# PIC32CX2051BZ66048 device description
Architecture: CORTEX-M4; Family: PIC32CX; Series: PIC32CXBZ66
Registers are 32-bit, read-write, reset 0x0 unless marked. A register's access mark holds for its fields unless they carry their own. Offsets are from the block's base; [hi:lo] are bit positions; lines under a group give offsets from that group; {n}, {i} and the like mark numbered series.

## USB
Instances: USB 0x44010000
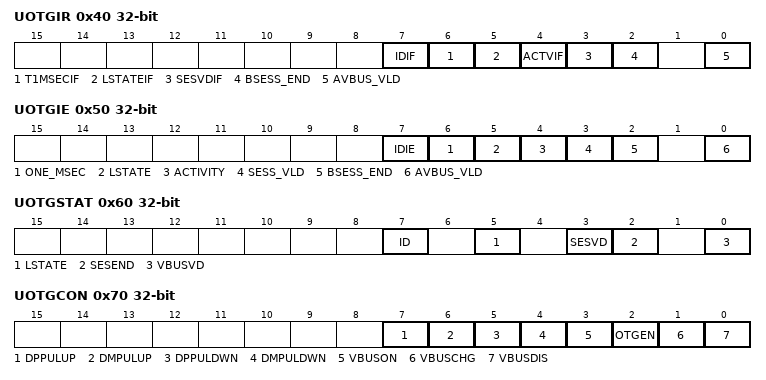
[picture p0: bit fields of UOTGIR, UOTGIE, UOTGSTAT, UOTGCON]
0x40 UOTGIR reset not defined — USB OTG Interrupt Status Register
  [7] IDIF — ID State Change Indicator bit
    1=DETECT (Change in ID state is detected); 0=NO_DETECT (No change in ID state is detected)
  [6] T1MSECIF — 1 Millisecond Timer bit
    1=EXPIRE (1ms timer has expired); 0=NOT_EXPIRE (1ms timer has not expired)
  [5] LSTATEIF — Line State Stable Indicator bit
    1=STABLE (USB line state has been stable for 1ms); 0=NOT_STABLE (USB line state has not been stable for 1ms)
  [4] ACTVIF — Bus Activity Indicator bit
    1=DETECT (Activity on the D+, D-, ID, or VBus lines has been detected); 0=NO_DETECT (Active has not been detected)
  [3] SESVDIF — Session Valid Change Indicator bit
    1=CHANGE (Change on usb_sess_vld input detected); 0=NO_CHANGED (No change on usb_sess_vld input detected)
  [2] BSESS_END — B-Device VBUS change indicator bit
    1=CHANGE (Change on usb_b_sess_end input detected); 0=NO_CHANGED (No change on usb_b_sess_end input detected)
  [0] AVBUS_VLD — A-VBUS change indicator bit
    1=CHANGE (Change on usb_a_vbus_vld input detected); 0=NO_CHANGE (No change on usb_a_vbus_vld input detected)
0x44 UOTGIRCLR
0x48 UOTGIRSET
0x4C UOTGIRINV
0x50 UOTGIE reset not defined — USB OTG Interrupt Enable Register
  [7] IDIE — ID Interrupt Enable bit
    1=ON (ID interrupt is enabled); 0=OFF (ID interrupt is disabled)
  [6] ONE_MSEC — 1 Millisecond Timer Interrupt Enable bit
    1=ON (1 millisecond timer interrupt is enabled); 0=OFF (1 millisecond timer interrupt is disabled)
  [5] LSTATE — Line State Interrupt Enable bit
    1=ON (Line state interrupt is enabled); 0=OFF (Line state interrupt is disabled)
  [4] ACTIVITY — Activity Interrupt Enable bit
    1=ON (ACTIVITY interrupt is enabled); 0=OFF (ACTIVITY interrupt is disabled)
  [3] SESS_VLD — Session Valid Interrupt Enable bit
    1=ON (Session valid interrupt is enabled); 0=OFF (Session valid interrupt is disabled)
  [2] BSESS_END — B-Session End Interrupt Enable bit
    1=ON (B-session end interrupt is enabled); 0=OFF (B-session end interrupt is disabled)
  [0] AVBUS_VLD — A- Vbus Valid Interrupt Enable bit
    1=ON (A-Vbus valid interrupt is enabled); 0=OFF (A-Vbus valid interrupt is disabled)
0x54 UOTGIECLR
0x58 UOTGIESET
0x5C UOTGIEINV
0x60 UOTGSTAT reset not defined — USB OTG Status Register
  [7] ID — ID Pin State Indicator bit
    1=NOT_PLUG (No cable is attached or a Type-B cable has been plugged into the USB receptacle); 0=PLUG (A Type-A cable has been plugged into the USB receptacle)
  [5] LSTATE — Line State Stable Indicator bit
    1=STABLE (USB line state (UCTRL[SE0 and JSTATE]) has been stable for the previous 1 ms); 0=NOT_STABLE (USB line state (UCTRL[SE0 and JSTATE]) has not been stable for the previous 1 ms)
  [3] SESVD — Session Valid Indicator bit
    1=ABOVE (Vbus voltage is above Session Valid on the A or B device); 0=BELOW (Vbus voltage is below Session Valid on the A or B device)
  [2] SESEND — B-Session End Indicator bit
    1=BELOW (Vbus voltage is below VB_SESS_END on the B device); 0=ABOVE (Vbus voltage is above VB_SESS_END on the B device)
  [0] VBUSVD — A-VBUS Valid Indicator bit
    1=ABOVE (Vbus voltage is above VA_VBUS_VLD on the A device); 0=BELOW (Vbus voltage is below VA_VBUS_VLD on the A device)
0x70 UOTGCON reset not defined — USB OTG Control Register
  [7] DPPULUP — D+ Pull-Up Enable bit
    1=ON (D+ data line pull-up resistor is enabled); 0=OFF (D+ data line pull-up resistor is disabled)
  [6] DMPULUP — D- Pull-Up Enable bit
    1=ON (D- data line pull-up resistor is enabled); 0=OFF (D- data line pull-up resistor is disabled)
  [5] DPPULDWN — D+ Pull-Down Enable bit
    1=ON (D+ data line pull-down resistor is enabled); 0=OFF (D+ data line pull-down resistor is disabled)
  [4] DMPULDWN — D- Pull-Down Enable bit
    1=ON (D- data line pull-down resistor is enabled); 0=OFF (D- data line pull-down resistor is disabled)
  [3] VBUSON — Vbus Power-on bit
    1=ON (Vbus line is powered); 0=OFF (Vbus line is not powered)
  [2] OTGEN — OTG Functionality Enable bit
    1=ON (DPPULUP); 0=OFF (DPPULUP)
  [1] VBUSCHG — Vbus Charge Enable bit
    1=CHG (Vbus line is charged through a pull-up resistor); 0=NOT_CHG (Vbus line is not charged through a resistor)
  [0] VBUSDIS — Vbus Discharge Enable bit
    1=DISCHG (Vbus line is discharged through a pull-down resistor); 0=NOT_DISCHG (Vbus line is not discharged through a resistor)
0x74 UOTGCONCLR
0x78 UOTGCONSET
0x7C UOTGCONINV
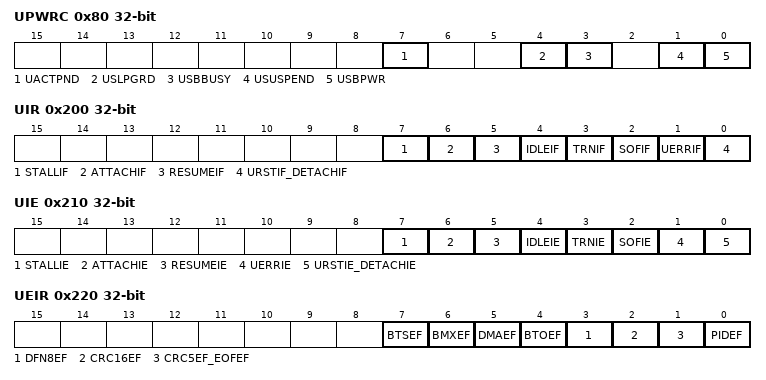
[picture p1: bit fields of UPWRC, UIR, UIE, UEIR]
0x80 UPWRC reset not defined — USB Power Control Register
  [7] UACTPND — USB Activity Pending bit
    1=CHANGE (USB hardware has detected a change in link status); 0=NORMAL (USB Hardware in normal operation mode)
  [4] USLPGRD — USB Sleep Entry Guard bit
    1=BLOCK_SLEEP (Sleep entry is blocked if USB bus activity is detected or if a notification is pending); 0=NO_BLOCK (USB module does not block Sleep entry)
  [3] USBBUSY — USB Module Busy bit
    1=ACTIVE_OR_DISALBE (USB module is active or disabled); 0=NOT_ACTIVE_AND_READY (USB module is not active and is ready to be enabled)
  [1] USUSPEND — USB Suspend Mode bit
    1=SUSPEND (USB module is placed in Suspend mode (The 48 MHz USB clock will be gated off. The transceiver is placed in a low-power state.)); 0=NORMAL (USB module operates normally)
  [0] USBPWR — USB Operation Enable bit
    1=ON (USB module is turned on); 0=OFF (USB module is disabled (Outputs held inactive)
0x84 UPWRCCLR
0x88 UPWRCSET
0x8C UPWRCINV
0x200 UIR reset not defined — USB Interrupt Register
  [7] STALLIF — STALL Handshake Interrupt bit
    1=HANDSHAKE (A STALL handshake was sent by Peripheral or received by Host during the handshake phase of the transaction); 0=NO_HANDSHAKE (STALL handshake has not been sent)
  [6] ATTACHIF — Peripheral Attach Interrupt bit
    1=DETECT (Peripheral attachment was detected by the USB module); 0=NOT_DETECT (Peripheral attachment was not detected)
  [5] RESUMEIF — Resume Interrupt bit
    1=K_STATE (K-State is observed on the D+ or D- pin for 2.5 s); 0=NORMAL (K-State is not observed)
  [4] IDLEIF — Idle Detect Interrupt bit
    1=IDLE (Idle condition detected (constant Idle state of 3 ms or more)); 0=NOT_IDLE (No Idle condition detected)
  [3] TRNIF — Token Processing Complete Interrupt bit
    1=READY (Processing of current token is complete; a read of the UxSTAT register will provide endpoint information); 0=NOT_READY (Processing of current token not complete)
  [2] SOFIF — SOF Token Interrupt bit
    1=SOF_RCVE (SOF token received by the peripheral or the SOF threshold reached by the host); 0=NO_SOF (SOF token was not received nor threshold reached)
  [1] UERRIF — USB Error Condition Interrupt bit
    1=ERROR (Unmasked error condition has occurred); 0=NO_ERROR (Unmasked error condition has not occurred)
  [0] URSTIF_DETACHIF — (Device mode) USB Reset Interrupt bit Device mode / (Host mode)USB Detach Interrupt bit Host mode
    1=DETECT ((Device mode)Valid USB Reset has occurred / (Host mode)Peripheral detachment was detected by the USB module); 0=NOT_DETECT ((Device mode)No USB Reset has occurred / (Host mode)Peripheral detachment was not detected)
0x204 UIRCLR
0x210 UIE reset not defined — USB Interrupt Enable Register
  [7] STALLIE — STALL Handshake Interrupt Enable bit
    1=ON (STALL interrupt is enabled); 0=OFF (STALL interrupt is disabled)
  [6] ATTACHIE — ATTACH Interrupt Enable bit
    1=ON (ATTACH interrupt is enabled); 0=OFF (ATTACH interrupt is disabled)
  [5] RESUMEIE — RESUME Interrupt Enable bit
    1=ON (RESUME interrupt is enabled); 0=OFF (RESUME interrupt is disabled)
  [4] IDLEIE — Idle Detect Interrupt Enable bit
    1=ON (Idle interrupt is enabled); 0=OFF (Idle interrupt is disabled)
  [3] TRNIE — Token Processing Complete Interrupt Enable bit
    1=ON (TRNIF interrupt is enabled); 0=OFF (TRNIF interrupt is disabled)
  [2] SOFIE — SOF Token Interrupt Enable bit
    1=ON (SOFIF interrupt is enabled); 0=OFF (SOFIF interrupt is disabled)
  [1] UERRIE — USB Error Interrupt Enable bit
    1=ON (USB Error interrupt is enabled); 0=OFF (USB Error interrupt is disabled)
  [0] URSTIE_DETACHIE — (Device mode) USB Reset Interrupt Enable bit Device mode / (Host mode)USB Detach Interrupt Enable bit Host Mode
    1=ON ((Device mode) URSTIF interrupt is enabled / (Host mode) DATTCHIF interrupt is enabled); 0=OFF ((Device mode) URSTIF interrupt is disabled / (Host mode) DATTCHIF interrupt is disabled)
0x214 UIECLR
0x218 UIESET
0x21C UIEINV
0x220 UEIR reset not defined — USB Error Interrupt Status Register
  [7] BTSEF — Bit Stuff Error Flag bit
    1=ERROR (Packet rejected due to bit stuff error); 0=NO_ERROR (Packet accepted)
  [6] BMXEF — Bus Matrix Error Flag bit
    1=ERROR (BVCI access initiated on BMX returned response error); 0=NO_ERROR (No address error)
  [5] DMAEF — DMA Error Flag bit
    1=ERROR (USB DMA error condition detected); 0=NO_ERROR (No DMA error)
  [4] BTOEF — Bus Turnaround Time-Out Error Flag bit
    1=TIMEOUT (Bus turnaround time-out has occurred); 0=NO_TIMEOUT (No bus turnaround time-out)
  [3] DFN8EF — Data Field Size Error Flag bit
    1=NOT_INTEGRAL (Data field received is not an integral number of bytes); 0=INTEGRAL (Data field received is an integral number of bytes)
  [2] CRC16EF — CRC16 Failure Flag bit
    1=ERROR (Data packet rejected due to CRC16 error); 0=NO_ERROR (Data packet accepted)
  [1] CRC5EF_EOFEF — (Device mode)CRC5 Host Error Flag bit / (Host mode)EOF Error Flag bit
    1=ERROR ((Device mode)Token packet rejected due to CRC5 error / (Host mode)EOF error condition detected); 0=NO_ERROR ((Device mode)Token packet accepted / (Host mode)No EOF error condition)
  [0] PIDEF — PID Check Failure Flag bit
    1=FAIL (PID check failed); 0=PASS (PID check passed)
0x224 UEIRCLR
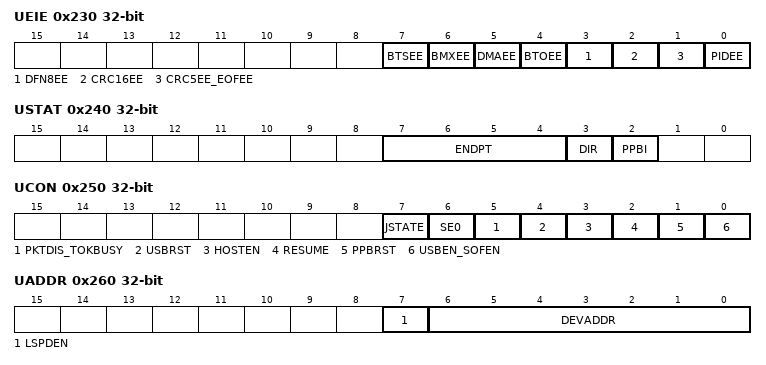
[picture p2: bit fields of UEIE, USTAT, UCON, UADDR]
0x230 UEIE reset not defined — USB Error Interrupt Enable Register
  [7] BTSEE — Bit Stuff Error Interrupt Enable bit
    1=ON (BTSEF interrupt is enabled); 0=OFF (BTSEF interrupt is disabled)
  [6] BMXEE — Bus Matrix Error Interrupt Enable bit
    1=ON (BMXEF interrupt is enabled); 0=OFF (BMXEF interrupt is disabled)
  [5] DMAEE — DMA Error Interrupt Enable bit
    1=ON (DMAEF interrupt is enabled); 0=OFF (DMAEF interrupt is disabled)
  [4] BTOEE — Bus Turnaround Time-out Error Interrupt Enable bit
    1=ON (BTOEF interrupt is enabled); 0=OFF (BTOEF interrupt is disabled)
  [3] DFN8EE — Data Field Size Error Interrupt Enable bit
    1=ON (DFN8EF interrupt is enabled); 0=OFF (DFN8EF interrupt is disabled)
  [2] CRC16EE — CRC16 Failure Interrupt Enable bit
    1=ON (CRC16EF interrupt is enabled); 0=OFF (CRC16EF interrupt is disabled)
  [1] CRC5EE_EOFEE — (Device mode) CRC5 Host Error Interrupt Enable bit / (Host mode) EOF Error Interrupt Enable bit
    1=ON ((Device mode)CRC5EF interrupt is enabled / (Host mode)EOF interrupt is enabled); 0=OFF ((Device mode)CRC5EF interrupt is disabled / (Host mode)EOF interrupt is disabled)
  [0] PIDEE — PID Check Failure Interrupt Enable bit
    1=ON (PIDEF interrupt is enabled); 0=OFF (PIDEF interrupt is disabled)
0x234 UEIECLR
0x238 UEIESET
0x23C UEIEINV
0x240 USTAT ro reset not defined — USB Status Register
  [7:4] ENDPT — Encoded Number of Last Endpoint Activity bits
    15=EP_15 (Endpoint 15); 14=EP_14 (Endpoint 14); 1=EP_1 (Endpoint 1); 0=EP_0 (Endpoint 0)
  [3] DIR — Last BD Direction Indicator bit
    1=TX (Last transaction was a transmit transfer (TX)); 0=RX (Last transaction was a receive transfer (RX))
  [2] PPBI — Ping-Pong BD Pointer Indicator bit
    1=ODD (The last transaction was to the ODD BD bank); 0=EVEN (The last transaction was to the EVEN BD bank)
0x244 USTATCLR
0x248 USTATSET
0x24C USTATINV
0x250 UCON reset not defined — USB Control Register
  [7] JSTATE — Live Differential Receiver JSTATE flag bit
    1=DETECT (JSTATE detected on the USB); 0=NOT_DETECT (No JSTATE detected)
  [6] SE0 — Live Single-Ended Zero flag bit
    1=DETECT (Single Ended Zero detected on the USB); 0=NOT_DETECT (No Single Ended Zero detected)
  [5] PKTDIS_TOKBUSY — (Device mode) Packet Transfer Disable bit / (Host mode) Token Busy Indicator bit
    1=ON ((Device mode)Token and packet processing disabled (set upon SETUP token received) / (Host mode)Token being executed by the USB module); 0=OFF ((Device mode)Token and packet processing enabled / (Host mode)No token being executed)
  [4] USBRST — Module Reset bit
    1=RESET_GENERATED (USB reset is generated); 0=RESET_TERMINATED (USB reset is terminated)
  [3] HOSTEN — Host Mode Enable bit
    1=ON (USB host capability is enabled); 0=OFF (USB host capability is disabled)
  [2] RESUME — RESUME Signaling Enable bit
    1=ON (RESUME signaling is activated); 0=OFF (RESUME signaling is disabled)
  [1] PPBRST — Ping-Pong Buffers Reset bit
    1=RESET (Reset all Even/Odd buffer pointers to the EVEN BD banks); 0=NO_RESET (Even/Odd buffer pointers not being Reset)
  [0] USBEN_SOFEN — (Device mode)USB Module Enable bit / (Host mode)
    1=ON ((Device mode)USB module and supporting circuitry is enabled / (Host mode)SOF token sent every 1 ms); 0=OFF ((Device mode)USB module and supporting circuitry is disabled / (Host mode)SOF token disabled)
0x254 UCONCLR
0x258 UCONSET
0x25C UCONINV
0x260 UADDR reset not defined — USB Address Register
  [7] LSPDEN — Low Speed Enable Indicator bit
    1=LOW_SPEED (Next token command to be executed at Low Speed); 0=FULL_SPEED (Next token command to be executed at Full Speed)
  [6:0] DEVADDR
0x264 UADDRCLR
0x268 UADDRSET
0x26C UADDRINV
0x270 UBDTP1 reset not defined — USB BDT Page 1 Register
  [7:1] BDTPTRL
0x274 UBDTP1CLR
0x278 UBDTP1SET
0x27C UBDTP1INV
0x280 UFRML ro reset not defined — USB Frame Number Low Register
  [7:0] FRML
0x284 UFRMLCLR
0x288 UFRMLSET
0x28C UFRMLINV
0x290 UFRMH ro reset not defined — USB Frame Number High Register
  [2:0] FRMH
0x294 UFRMHCLR
0x298 UFRMHSET
0x29C UFRMHINV
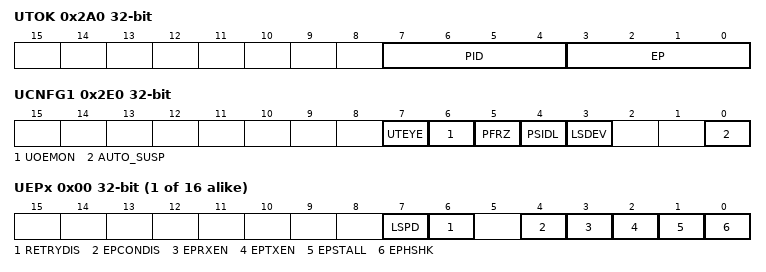
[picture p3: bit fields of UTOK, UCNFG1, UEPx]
0x2A0 UTOK reset not defined — USB Token Register
  [7:4] PID — Token Type Indicator bits
    1=OUT (OUT (TX) token type transaction); 9=IN (IN (RX) token type transaction); 13=SETUP (SETUP (TX) token type transaction)
  [3:0] EP
0x2A4 UTOKCLR
0x2A8 UTOKSET
0x2AC UTOKINV
0x2B0 USOF reset not defined — USB SOF Threshold Register
  [7:0] CNT — SOF Threshold Value bits
    74=BYTE64 (64-byte packet); 42=BYTE32 (32-byte packet); 26=BYTE16 (16-byte packet); 18=BYTE8 (8-byte packet)
0x2B4 USOFCLR
0x2B8 USOFSET
0x2BC USOFINV
0x2C0 UBDTP2 reset not defined — USB BDT PAGE 2 Register
  [7:0] BDTPTRH
0x2C4 UBDTP2CLR
0x2C8 UBDTP2SET
0x2CC UBDTP2INV
0x2D0 UBDTP3 reset not defined — USB BDT PAGE 3 Register
  [7:0] BDTPTRU
0x2D4 UBDTP3CLR
0x2D8 UBDTP3SET
0x2DC UBDTP3INV
0x2E0 UCNFG1 reset not defined — USB Configuration 1 Register
  [7] UTEYE — USB Eye-Pattern Test Enable bit
    1=ON (Eye-Pattern Test is enabled); 0=OFF (Eye-Pattern Test is disabled)
  [6] UOEMON — USB
    1=ACTIVE (OE signal is active; it indicates intervals during which the D+/D- lines are driving); 0=INACTIVE (OE signal is inactive)
  [5] PFRZ — Freeze in Debug mode
    1=FREEZE (When emulator is in Debug mode, module freezes operation); 0=NOT_FREEZE (When emulator is in Debug mode, module continues operation)
  [4] PSIDL — Stop in Idle Mode bit
    1=DISCONTINUE (Discontinue module operation when device enters Idle mode); 0=CONTINUE (Continue module operation in Idle mode)
  [3] LSDEV — Low-Speed Device Enable bit
    1=LOW_SPEED (USB module to operate in Low-Speed Device mode); 0=OTG (USB module to operate in OTG)
  [0] AUTO_SUSP — Automatic Suspend Enable bit
    1=AUTO_SUSPEND (USB module automatically suspends upon entry to Sleep mode. See the USUSPEND bit (UxPWRC) in); 0=NO_AUTO_SUSPEND (USB module does not automatically suspend upon entry to Sleep mode. Software must use the USUSPEND bit (UxPWRC) to suspend the module)
0x2E4 UCNFG1CLR
0x2E8 UCNFG1SET
0x2EC UCNFG1INV
{0x300+0x10*i} USB_UEP[{i}] (i=0..15) group
  0x00 UEPx reset not defined — USB Endpoint Control Registers
    [7] LSPD — Low-Speed Direct Connection Enable bit
      1=ON (Direct connection to a low-speed device is enabled); 0=OFF (Direct connection to a low-speed device is disabled; hub required with PRE_PID)
    [6] RETRYDIS — Retry Disable bit
      1=ON (Retry NAKed transactions is disabled); 0=OFF (Retry NAKed transactions is enabled; retry done in hardware)
    [4] EPCONDIS — Bidirectional Endpoint Control bit
      1=DISABLE_1 ((If EPTXEN is 1 and EPRXEN is 1)Disable Endpoint 1 from Control transfers; only TX and RX transfers allowed / (else)bit is ignored); 0=ENABLE_1 ((If EPTXEN is 1 and EPRXEN is 1)Enable Endpoint 1 for Control (SETUP) transfers; TX and RX transfers also allowed / (else)bit is ignored)
    [3] EPRXEN — Endpoint Receive Enable bit
      1=ON (Endpoint 1 receive is enabled); 0=OFF (Endpoint 1 receive is disabled)
    [2] EPTXEN — Endpoint Transmit Enable bit
      1=ON (Endpoint 1 transmit is enabled); 0=OFF (Endpoint 1 transmit is disabled)
    [1] EPSTALL — Endpoint Stall Status bit
      1=STALL (Endpoint 1 was stalled); 0=NOT_STALL (Endpoint 1 was not stalled)
    [0] EPHSHK — Endpoint Handshake Enable bit
      1=ON (Endpoint Handshake is enabled); 0=OFF (Endpoint Handshake is disabled (typically used for isochronous endpoints))
  0x04 UEPxCLR
  0x08 UEPxSET
  0x0C UEPxINV
